# STM32F334x register map
File version: 1.0
Registers are 32-bit, read-write, reset 0x0 unless marked. A register's access mark holds for its fields unless they carry their own. Offsets are from the block's base; [hi:lo] are bit positions; lines under a group give offsets from that group; {n}, {i} and the like mark numbered series.

## GPIOA — General-purpose I/Os
Base 0x48000000
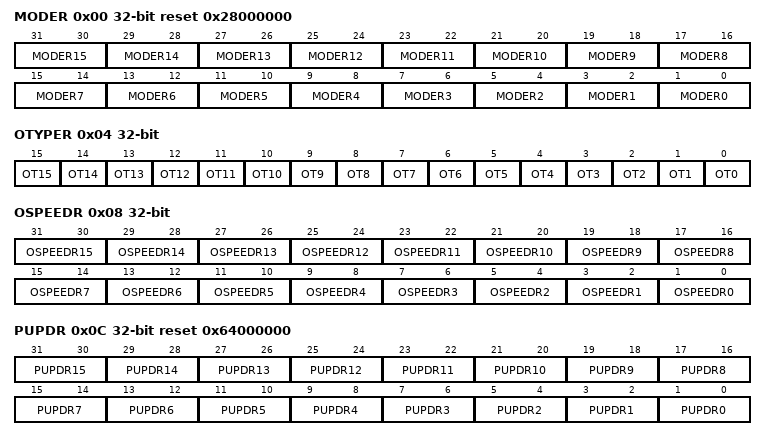
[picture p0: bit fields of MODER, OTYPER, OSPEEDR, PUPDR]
0x00 MODER reset 0x28000000 — GPIO port mode register
  [all] fields
    0=Input mode (reset state); 1=Output (General purpose output mode); 2=Alternate function mode; 3=Analog mode
  [2n+1:2n] MODER{n} (n=0..15) — Pin {n} mode
0x04 OTYPER — GPIO port output type register
  [all] fields
    0=push_pull (Output push-pull (reset state)); 1=open_drain (Output open-drain)
  [n] OT{n} (n=0..15) — Pin {n} output type
0x08 OSPEEDR — GPIO port output speed register
  [all] fields
    0=Low_speed; 1=Medium_speed; 3=High_speed
  [2n+1:2n] OSPEEDR{n} (n=8..15) — Pin {n} output speed
  [15:14] OSPEEDR7 — Pin 8 output speed
  [2n+1:2n] OSPEEDR{n} (n=0..6) — Pin {n} output speed
0x0C PUPDR reset 0x64000000 — GPIO port pull-up/pull-down register
  [all] fields
    0=None (No pull-up, pull-down); 1=Pull_up; 2=Pull_down
  [2n+1:2n] PUPDR{n} (n=0..15) — Pin {n} pull-up/pull-down state
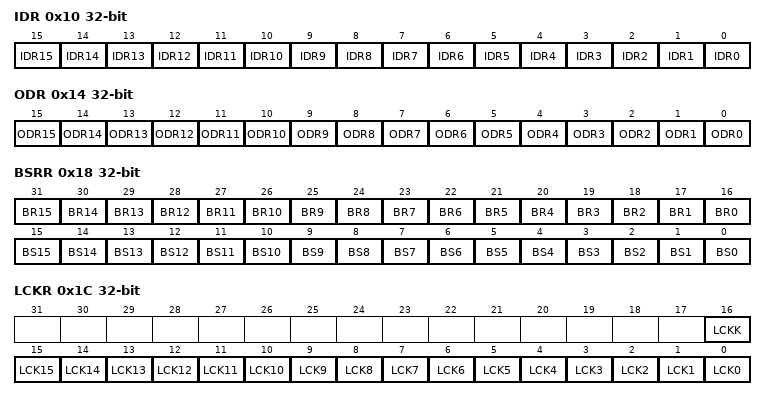
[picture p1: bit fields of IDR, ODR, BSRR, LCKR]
0x10 IDR ro (reset mask 0xFFFF0000) — GPIO port input data register
  [n] IDR{n} (n=0..15) — Pin {n} input data
0x14 ODR — GPIO port output data register
  [n] ODR{n} (n=0..15) — Pin {n} output data
0x18 BSRR wo — GPIO port bit set/reset register
  [n+16] BR{n} (n=0..15) — Pin {n} reset bit
  [n] BS{n} (n=0..15) — Pin {n} set bit
0x1C LCKR — GPIO port configuration lock register
  [16] LCKK — Lock Key
  [n] LCK{n} (n=0..15)
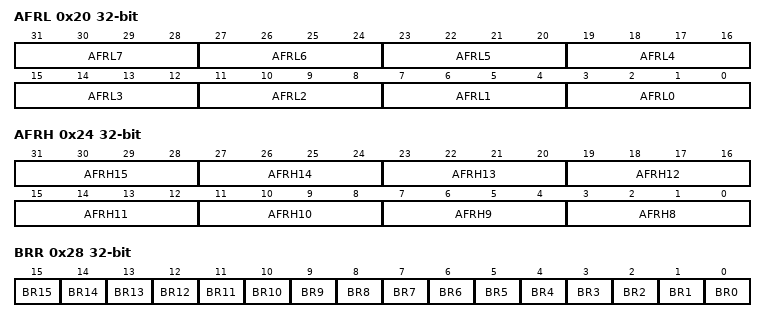
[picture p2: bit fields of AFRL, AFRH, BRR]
0x20 AFRL — GPIO alternate function low register
  [all] fields
    {v}=AF{v} (v=0..15)
  [31:28] AFRL7 — Alternate function for pin 7
  [4n+3:4n] AFRL{n} (n=0..6)
0x24 AFRH — GPIO alternate function high register
  [all] fields
    {v}=AF{v} (v=0..15)
  [4n-29:4n-32] AFRH{n} (n=8..15)
0x28 BRR wo — Port bit reset register
  [n] BR{n} (n=0..15)

## GPIOB — General-purpose I/Os
Base 0x48000400
Same registers: GPIOC 0x48000800, GPIOD 0x48000C00, GPIOF 0x48001400
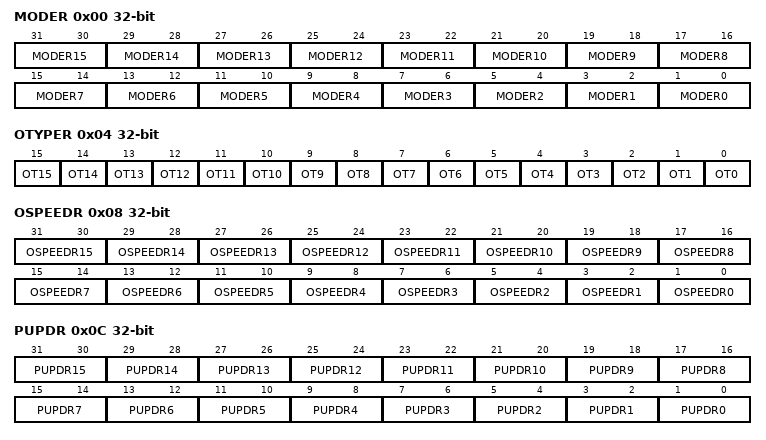
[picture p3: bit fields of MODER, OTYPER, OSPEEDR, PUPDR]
0x00 MODER — GPIO port mode register
  [all] fields
    0=Input mode (reset state); 1=Output (General purpose output mode); 2=Alternate function mode; 3=Analog mode
  [2n+1:2n] MODER{n} (n=0..15) — Pin {n} mode
0x04 OTYPER — GPIO port output type register
  [all] fields
    0=push_pull (Output push-pull (reset state)); 1=open_drain (Output open-drain)
  [n] OT{n} (n=0..15) — Pin {n} output type
0x08 OSPEEDR — GPIO port output speed register
  [all] fields
    0=Low_speed; 1=Medium_speed; 3=High_speed
  [2n+1:2n] OSPEEDR{n} (n=0..15) — Pin {n} output speed
0x0C PUPDR — GPIO port pull-up/pull-down register
  [all] fields
    0=None (No pull-up, pull-down); 1=Pull_up; 2=Pull_down
  [2n+1:2n] PUPDR{n} (n=0..15) — Pin {n} pull-up/pull-down state
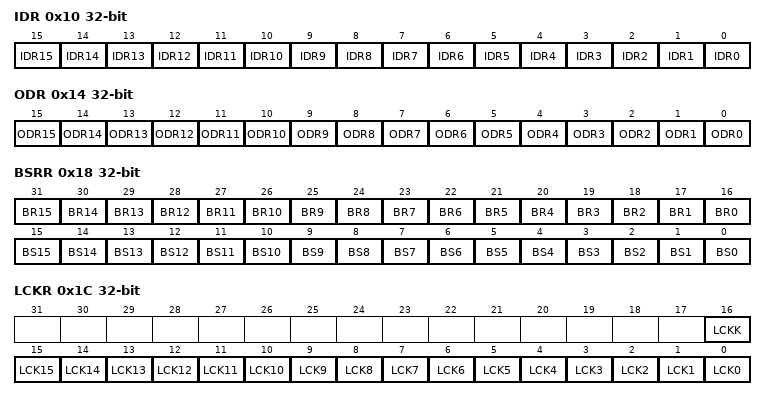
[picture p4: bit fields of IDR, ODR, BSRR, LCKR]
0x10 IDR ro — GPIO port input data register
  [n] IDR{n} (n=0..15) — Pin {n} input data
0x14 ODR — GPIO port output data register
  [n] ODR{n} (n=0..15) — Pin {n} output data
0x18 BSRR wo — GPIO port bit set/reset register
  [n+16] BR{n} (n=0..15) — Pin {n} reset bit
  [n] BS{n} (n=0..15) — Pin {n} set bit
0x1C LCKR — GPIO port configuration lock register
  [16] LCKK — Lock Key
  [n] LCK{n} (n=0..15)
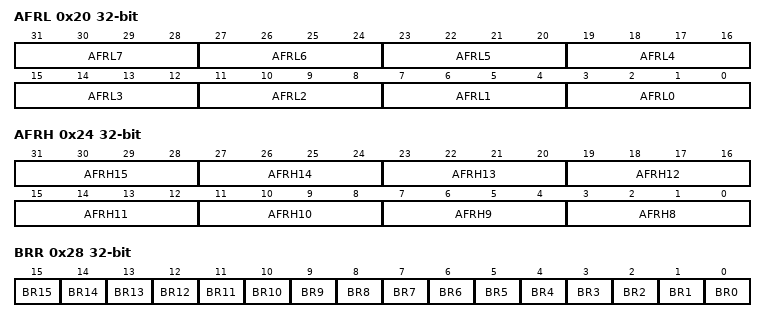
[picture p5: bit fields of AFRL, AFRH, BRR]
0x20 AFRL — GPIO alternate function low register
  [all] fields
    {v}=AF{v} (v=0..15)
  [4n+3:4n] AFRL{n} (n=0..7) — Alternate function selection for port x bit y (y = 0..7)
0x24 AFRH — GPIO alternate function high register
  [all] fields
    {v}=AF{v} (v=0..15)
  [4n-29:4n-32] AFRH{n} (n=8..15) — Alternate function selection for port x bit y (y = 8..15)
0x28 BRR wo — Port bit reset register
  [n] BR{n} (n=0..15)

## TSC — Touch sensing controller
Base 0x40024000
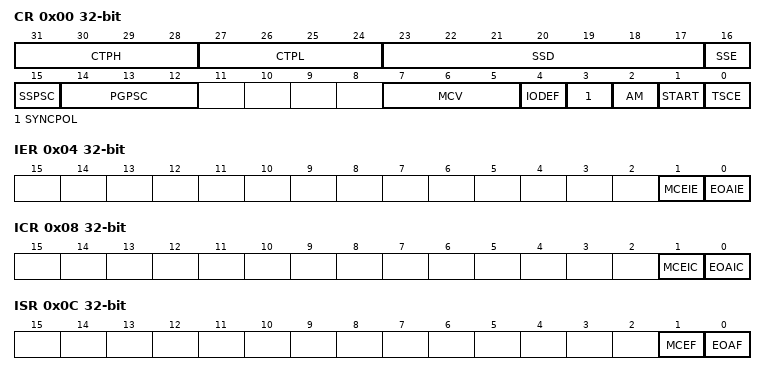
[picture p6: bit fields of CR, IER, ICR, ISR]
0x00 CR — control register
  [31:28] CTPH — Charge transfer pulse high
  [27:24] CTPL — Charge transfer pulse low
  [23:17] SSD — Spread spectrum deviation
  [16] SSE — Spread spectrum enable
  [15] SSPSC — Spread spectrum prescaler
  [14:12] PGPSC — pulse generator prescaler
  [7:5] MCV — Max count value
  [4] IODEF — I/O Default mode
  [3] SYNCPOL — Synchronization pin polarity
  [2] AM — Acquisition mode
  [1] START — Start a new acquisition
  [0] TSCE — Touch sensing controller enable
0x04 IER — interrupt enable register
  [1] MCEIE — Max count error interrupt enable
  [0] EOAIE — End of acquisition interrupt enable
0x08 ICR — interrupt clear register
  [1] MCEIC — Max count error interrupt clear
  [0] EOAIC — End of acquisition interrupt clear
0x0C ISR — interrupt status register
  [1] MCEF — Max count error flag
  [0] EOAF — End of acquisition flag
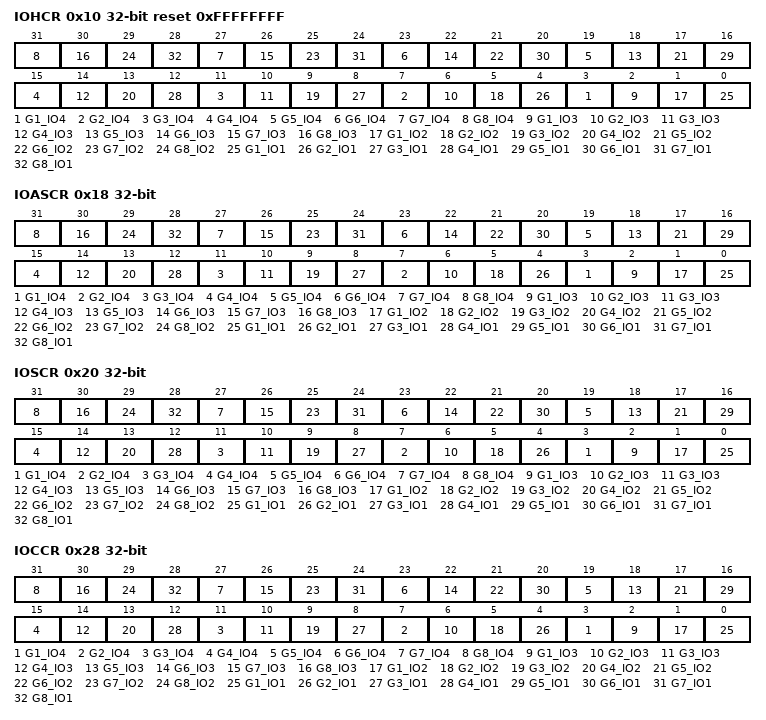
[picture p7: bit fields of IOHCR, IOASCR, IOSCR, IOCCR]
0x10 IOHCR reset 0xFFFFFFFF — I/O hysteresis control register
  [4n-1] G{n}_IO4 (n=1..8) — G{n}_IO4 Schmitt trigger hysteresis mode
  [4n-2] G{n}_IO3 (n=1..8) — G{n}_IO3 Schmitt trigger hysteresis mode
  [4n-3] G{n}_IO2 (n=1..8) — G{n}_IO2 Schmitt trigger hysteresis mode
  [4n-4] G{n}_IO1 (n=1..8) — G{n}_IO1 Schmitt trigger hysteresis mode
0x18 IOASCR — I/O analog switch control register
  [4n-1] G{n}_IO4 (n=1..8) — G{n}_IO4 analog switch enable
  [4n-2] G{n}_IO3 (n=1..8) — G{n}_IO3 analog switch enable
  [4n-3] G{n}_IO2 (n=1..8) — G{n}_IO2 analog switch enable
  [4n-4] G{n}_IO1 (n=1..8) — G{n}_IO1 analog switch enable
0x20 IOSCR — I/O sampling control register
  [4n-1] G{n}_IO4 (n=1..8) — G{n}_IO4 sampling mode
  [4n-2] G{n}_IO3 (n=1..8) — G{n}_IO3 sampling mode
  [4n-3] G{n}_IO2 (n=1..8) — G{n}_IO2 sampling mode
  [4n-4] G{n}_IO1 (n=1..8) — G{n}_IO1 sampling mode
0x28 IOCCR — I/O channel control register
  [4n-1] G{n}_IO4 (n=1..8) — G{n}_IO4 channel mode
  [4n-2] G{n}_IO3 (n=1..8) — G{n}_IO3 channel mode
  [4n-3] G{n}_IO2 (n=1..8) — G{n}_IO2 channel mode
  [4n-4] G{n}_IO1 (n=1..8) — G{n}_IO1 channel mode
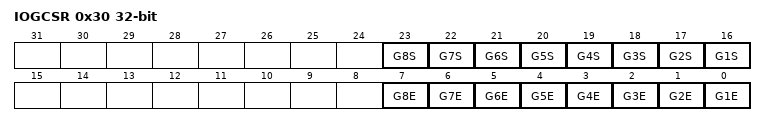
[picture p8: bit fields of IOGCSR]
0x30 IOGCSR access per field — I/O group control status register
  [23] G8S rw — Analog I/O group x status
  [22] G7S rw — Analog I/O group x status
  [n+15] G{n}S ro (n=1..6) — Analog I/O group x status
  [n-1] G{n}E rw (n=1..8) — Analog I/O group x enable
{0x30+4i} IOG{i}CR ro (i=1..8) — I/O group x counter register
  [13:0] CNT — Counter value
